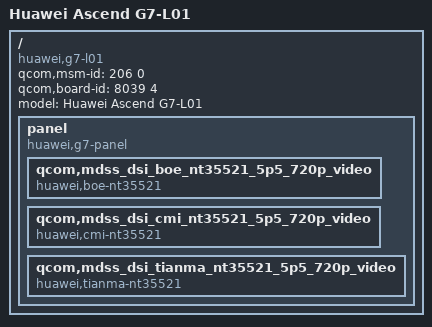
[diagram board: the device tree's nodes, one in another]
// SPDX-License-Identifier: GPL-2.0-only

/dts-v1/;

#include <skeleton.dtsi>

/ {
	qcom,msm-id = <206 0>;
	qcom,board-id = <8039 4>;

	model = "Huawei Ascend G7-L01";
	compatible = "huawei,g7-l01", "qcom,msm8916", "lk2nd,device";

	panel {
		compatible = "huawei,g7-panel";

		qcom,mdss_dsi_boe_nt35521_5p5_720p_video {
			compatible = "huawei,boe-nt35521";
		};
		qcom,mdss_dsi_cmi_nt35521_5p5_720p_video {
			compatible = "huawei,cmi-nt35521";
		};
		qcom,mdss_dsi_tianma_nt35521_5p5_720p_video {
			compatible = "huawei,tianma-nt35521";
		};
	};
};
